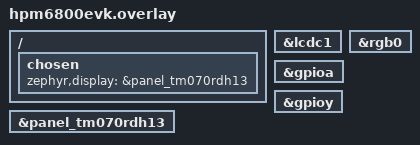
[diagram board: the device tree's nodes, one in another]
/*
 * Copyright 2024 HPMicro
 * SPDX-License-Identifier: Apache-2.0
 */

/ {
    chosen {
        zephyr,display = &panel_tm070rdh13;
    };
};

&lcdc1 {
    status = "okay";
};

&rgb0 {
    status = "okay";
};

&panel_tm070rdh13 {
    status = "okay";
};

/*
 * backlight control
 */
&gpioa {
    status = "okay";
};

&gpioy {
    status = "okay";
};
